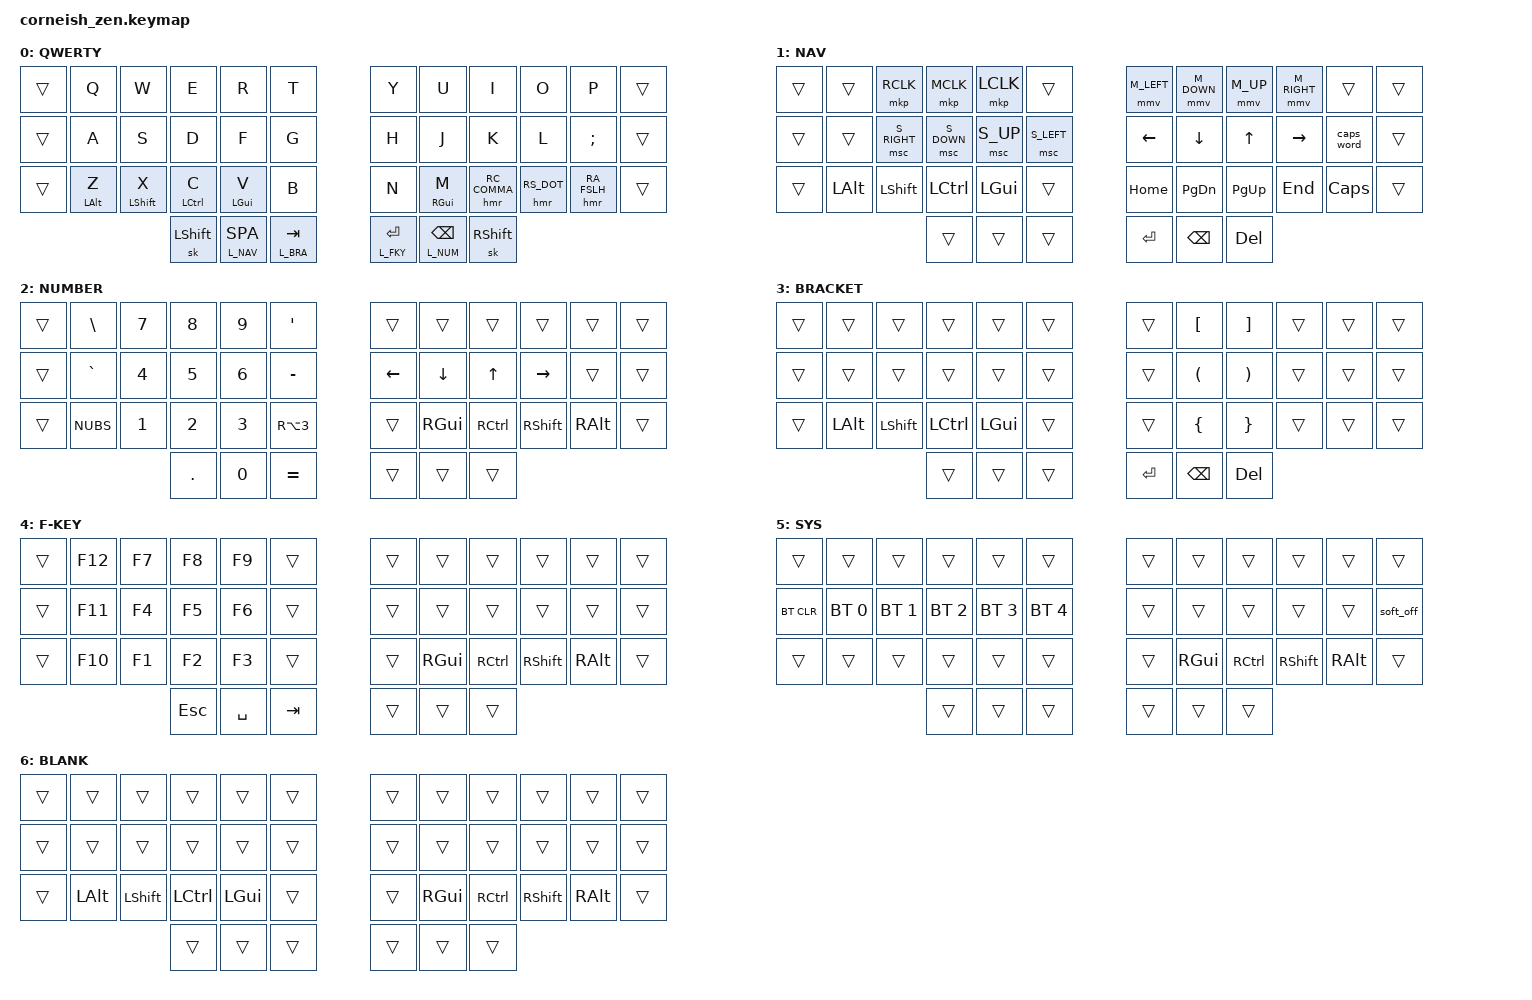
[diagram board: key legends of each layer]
#include <behaviors.dtsi>
#include <dt-bindings/zmk/keys.h>
#include <dt-bindings/zmk/bt.h>
#include <dt-bindings/zmk/mouse.h>

#include "42.h"

#define XXX &none
#define ___ &trans

#define RC_COMMA RCTRL COMMA
#define RS_DOT   RSHFT DOT
#define RA_FSLH  RALT FSLH

#define SPA SPACE

#define M_LEFT  MOVE_LEFT
#define M_RIGHT MOVE_RIGHT
#define M_DOWN  MOVE_DOWN
#define M_UP    MOVE_UP

#define S_LEFT  SCRL_LEFT
#define S_RIGHT SCRL_RIGHT
#define S_DOWN  SCRL_DOWN
#define S_UP    SCRL_UP

#define L_DEF 0
#define L_NAV 1
#define L_NUM 2
#define L_BRA 3
#define L_FKY 4
#define L_SYS 5

/ {
    chosen {
        zmk,matrix-transform = &default_transform;
    };
};

/ {
    conditional_layers {
        compatible = "zmk,conditional-layers";
        tri_layer {
            if-layers = <L_NAV L_BRA>;
            then-layer = <L_SYS>;
        };
    };
};

&soft_off {
    hold-time-ms = <2000>; // 2 second hold required
};

/ {
    behaviors {
        hml: homerow_mods_left {
            compatible = "zmk,behavior-hold-tap";
            #binding-cells = <2>;
            flavor = "balanced";
            tapping-term-ms = <280>;
            quick-tap-ms = <175>;
            require-prior-idle-ms = <125>;
            bindings = <&kp>, <&kp>;
            hold-trigger-key-positions = <KEYS_R THUMBS>;
            hold-trigger-on-release;
        };
        hmr: homerow_mods_right {
            compatible = "zmk,behavior-hold-tap";
            #binding-cells = <2>;
            flavor = "balanced";
            tapping-term-ms = <280>;
            quick-tap-ms = <175>;
            require-prior-idle-ms = <125>;
            bindings = <&kp>, <&kp>;
            hold-trigger-key-positions = <KEYS_L THUMBS>;
            hold-trigger-on-release;
        };
        lt: layer_tap {
            compatible = "zmk,behavior-hold-tap";
            #binding-cells = <2>;
            flavor = "tap-preferred";
            tapping-term-ms = <280>;
            quick-tap-ms = <175>;
            bindings = <&mo>, <&kp>;
        };
        sk: sticky_key {
            compatible = "zmk,behavior-sticky-key";
            #binding-cells = <1>;
            release-after-ms = <1000>;
            bindings = <&kp>;
            ignore-modifiers;
        };
    };
    combos {
        compatible = "zmk,combos";
        combo_esc {
            timeout-ms = <50>;
            key-positions = <RM1 RM2>;
            bindings = <&kp ESC>;
            layers = <L_DEF>;
            require-prior-idle-ms = <125>;
        };
    };
    keymap {
        compatible = "zmk,keymap";

        default_layer {
            display-name = "QWERTY";
            bindings = <
//╭─────────────╮ ╭─────────────┬─────────────┬─────────────┬─────────────┬─────────────╮ ╭─────────────┬─────────────┬─────────────┬─────────────┬─────────────╮ ╭─────────────╮
    ___             &kp Q         &kp W         &kp E         &kp R         &kp T           &kp Y         &kp U         &kp I         &kp O         &kp P           ___
//├─────────────┤ ├─────────────┼─────────────┼─────────────┼─────────────┼─────────────┤ ├─────────────┼─────────────┼─────────────┼─────────────┼─────────────┤ ├─────────────┤
    ___             &kp A         &kp S         &kp D         &kp F         &kp G           &kp H         &kp  J        &kp K         &kp L         &kp SEMI        ___
//├─────────────┤ ├─────────────┼─────────────┼─────────────┼─────────────┼─────────────┤ ├─────────────┼─────────────┼─────────────┼─────────────┼─────────────┤ ├─────────────┤
    ___             &hml LALT Z   &hml LSHFT X  &hml LCTRL C  &hml LGUI V   &kp B           &kp N         &hmr RGUI M   &hmr RC_COMMA &hmr RS_DOT   &hmr RA_FSLH    ___
//╰─────────────╯ ╰─────────────┴─────────────┼─────────────┼─────────────┼─────────────┤ ├─────────────┼─────────────┼─────────────┼─────────────┴─────────────╯ ╰─────────────╯
                                                &sk LSHIFT    &lt L_NAV SPA &lt L_BRA TAB   &lt L_FKY RET &lt L_NUM BSPC &sk RSHIFT
//                                            ╰─────────────┴─────────────┴─────────────╯ ╰─────────────┴─────────────┴─────────────╯
            >;
        };

        nav_layer {
            display-name = "NAV";
            bindings = <
//╭─────────────╮ ╭─────────────┬─────────────┬─────────────┬─────────────┬─────────────╮ ╭─────────────┬─────────────┬─────────────┬─────────────┬─────────────╮ ╭─────────────╮
    ___             ___           &mkp RCLK     &mkp MCLK     &mkp LCLK     ___             &mmv M_LEFT   &mmv M_DOWN   &mmv M_UP     &mmv M_RIGHT  ___             ___
//├─────────────┤ ├─────────────┼─────────────┼─────────────┼─────────────┼─────────────┤ ├─────────────┼─────────────┼─────────────┼─────────────┼─────────────┤ ├─────────────┤
    ___             ___           &msc S_RIGHT  &msc S_DOWN   &msc S_UP     &msc S_LEFT     &kp LEFT      &kp DOWN      &kp UP        &kp RIGHT     &caps_word      ___
//├─────────────┤ ├─────────────┼─────────────┼─────────────┼─────────────┼─────────────┤ ├─────────────┼─────────────┼─────────────┼─────────────┼─────────────┤ ├─────────────┤
    ___             &kp LALT      &kp LSHIFT    &kp LCTRL     &kp LGUI      ___             &kp HOME      &kp PG_DN     &kp PG_UP     &kp END       &kp CAPS        ___
//╰─────────────╯ ╰─────────────┴─────────────┼─────────────┼─────────────┼─────────────┤ ├─────────────┼─────────────┼─────────────┼─────────────┴─────────────╯ ╰─────────────╯
                                                ___           ___           ___             &kp RET       &kp BSPC      &kp DEL
//                                            ╰─────────────┴─────────────┴─────────────╯ ╰─────────────┴─────────────┴─────────────╯
            >;
        };

        number_layer {
            display-name = "NUMBER";
            bindings = <
//╭─────────────╮ ╭─────────────┬─────────────┬─────────────┬─────────────┬─────────────╮ ╭─────────────┬─────────────┬─────────────┬─────────────┬─────────────╮ ╭─────────────╮
    ___             &kp BSLH      &kp N7        &kp N8        &kp N9        &kp APOS        ___           ___           ___           ___           ___             ___
//├─────────────┤ ├─────────────┼─────────────┼─────────────┼─────────────┼─────────────┤ ├─────────────┼─────────────┼─────────────┼─────────────┼─────────────┤ ├─────────────┤
    ___             &kp GRAVE     &kp N4        &kp N5        &kp N6        &kp MINUS       &kp LEFT      &kp DOWN      &kp UP        &kp RIGHT     ___             ___
//├─────────────┤ ├─────────────┼─────────────┼─────────────┼─────────────┼─────────────┤ ├─────────────┼─────────────┼─────────────┼─────────────┼─────────────┤ ├─────────────┤
    ___             &kp NUBS      &kp N1        &kp N2        &kp N3        &kp RA(N3)      ___           &kp RGUI      &kp RCTRL     &kp RSHIFT    &kp RALT        ___
//╰─────────────╯ ╰─────────────┴─────────────┼─────────────┼─────────────┼─────────────┤ ├─────────────┼─────────────┼─────────────┼─────────────┴─────────────╯ ╰─────────────╯
                                                &kp DOT       &kp N0        &kp EQUAL       ___           ___           ___
//                                            ╰─────────────┴─────────────┴─────────────╯ ╰─────────────┴─────────────┴─────────────╯
            >;
        };

        bracket_layer {
            display-name = "BRACKET";
            bindings = <
//╭─────────────╮ ╭─────────────┬─────────────┬─────────────┬─────────────┬─────────────╮ ╭─────────────┬─────────────┬─────────────┬─────────────┬─────────────╮ ╭─────────────╮
    ___             ___           ___           ___           ___           ___             ___           &kp LBKT      &kp RBKT      ___           ___             ___
//├─────────────┤ ├─────────────┼─────────────┼─────────────┼─────────────┼─────────────┤ ├─────────────┼─────────────┼─────────────┼─────────────┼─────────────┤ ├─────────────┤
    ___             ___           ___           ___           ___           ___             ___           &kp LPAR      &kp RPAR      ___           ___             ___
//├─────────────┤ ├─────────────┼─────────────┼─────────────┼─────────────┼─────────────┤ ├─────────────┼─────────────┼─────────────┼─────────────┼─────────────┤ ├─────────────┤
    ___             &kp LALT      &kp LSHIFT    &kp LCTRL     &kp LGUI      ___             ___           &kp LBRC      &kp RBRC      ___           ___             ___
//╰─────────────╯ ╰─────────────┴─────────────┼─────────────┼─────────────┼─────────────┤ ├─────────────┼─────────────┼─────────────┼─────────────┴─────────────╯ ╰─────────────╯
                                                ___           ___           ___             &kp RET       &kp BSPC      &kp DEL
//                                            ╰─────────────┴─────────────┴─────────────╯ ╰─────────────┴─────────────┴─────────────╯
            >;
        };

        fkey_layer {
            display-name = "F-KEY";
            bindings = <
//╭─────────────╮ ╭─────────────┬─────────────┬─────────────┬─────────────┬─────────────╮ ╭─────────────┬─────────────┬─────────────┬─────────────┬─────────────╮ ╭─────────────╮
    ___             &kp F12       &kp F7        &kp F8        &kp F9        ___             ___           ___           ___           ___           ___             ___
//├─────────────┤ ├─────────────┼─────────────┼─────────────┼─────────────┼─────────────┤ ├─────────────┼─────────────┼─────────────┼─────────────┼─────────────┤ ├─────────────┤
    ___             &kp F11       &kp F4        &kp F5        &kp F6        ___             ___           ___           ___           ___           ___             ___
//├─────────────┤ ├─────────────┼─────────────┼─────────────┼─────────────┼─────────────┤ ├─────────────┼─────────────┼─────────────┼─────────────┼─────────────┤ ├─────────────┤
    ___             &kp F10       &kp F1        &kp F2        &kp F3        ___             ___           &kp RGUI      &kp RCTRL     &kp RSHIFT    &kp RALT        ___
//╰─────────────╯ ╰─────────────┴─────────────┼─────────────┼─────────────┼─────────────┤ ├─────────────┼─────────────┼─────────────┼─────────────┴─────────────╯ ╰─────────────╯
                                                &kp ESC       &kp SPACE     &kp TAB         ___           ___           ___
//                                            ╰─────────────┴─────────────┴─────────────╯ ╰─────────────┴─────────────┴─────────────╯
            >;
        };

        sys_layer {
            display-name = "SYS";
            bindings = <
//╭─────────────╮ ╭─────────────┬─────────────┬─────────────┬─────────────┬─────────────╮ ╭─────────────┬─────────────┬─────────────┬─────────────┬─────────────╮ ╭─────────────╮
    ___             ___           ___           ___           ___           ___             ___           ___           ___           ___           ___             ___
//├─────────────┤ ├─────────────┼─────────────┼─────────────┼─────────────┼─────────────┤ ├─────────────┼─────────────┼─────────────┼─────────────┼─────────────┤ ├─────────────┤
   &bt BT_CLR      &bt BT_SEL 0  &bt BT_SEL 1  &bt BT_SEL 2  &bt BT_SEL 3  &bt BT_SEL 4     ___           ___           ___           ___           ___             &soft_off
//├─────────────┤ ├─────────────┼─────────────┼─────────────┼─────────────┼─────────────┤ ├─────────────┼─────────────┼─────────────┼─────────────┼─────────────┤ ├─────────────┤
    ___             ___           ___           ___           ___           ___             ___           &kp RGUI      &kp RCTRL     &kp RSHIFT    &kp RALT        ___
//╰─────────────╯ ╰─────────────┴─────────────┼─────────────┼─────────────┼─────────────┤ ├─────────────┼─────────────┼─────────────┼─────────────┴─────────────╯ ╰─────────────╯
                                                ___           ___           ___             ___           ___           ___
//                                            ╰─────────────┴─────────────┴─────────────╯ ╰─────────────┴─────────────┴─────────────╯
            >;
        };

        blank_layer {
            display-name = "BLANK";
            bindings = <
//╭─────────────╮ ╭─────────────┬─────────────┬─────────────┬─────────────┬─────────────╮ ╭─────────────┬─────────────┬─────────────┬─────────────┬─────────────╮ ╭─────────────╮
    ___             ___           ___           ___           ___           ___             ___           ___           ___           ___           ___             ___
//├─────────────┤ ├─────────────┼─────────────┼─────────────┼─────────────┼─────────────┤ ├─────────────┼─────────────┼─────────────┼─────────────┼─────────────┤ ├─────────────┤
    ___             ___           ___           ___           ___           ___             ___           ___           ___           ___           ___             ___
//├─────────────┤ ├─────────────┼─────────────┼─────────────┼─────────────┼─────────────┤ ├─────────────┼─────────────┼─────────────┼─────────────┼─────────────┤ ├─────────────┤
    ___             &kp LALT      &kp LSHIFT    &kp LCTRL     &kp LGUI      ___             ___           &kp RGUI      &kp RCTRL     &kp RSHIFT    &kp RALT        ___
//╰─────────────╯ ╰─────────────┴─────────────┼─────────────┼─────────────┼─────────────┤ ├─────────────┼─────────────┼─────────────┼─────────────┴─────────────╯ ╰─────────────╯
                                                ___           ___           ___             ___           ___           ___
//                                            ╰─────────────┴─────────────┴─────────────╯ ╰─────────────┴─────────────┴─────────────╯
            >;
        };
    };
};
